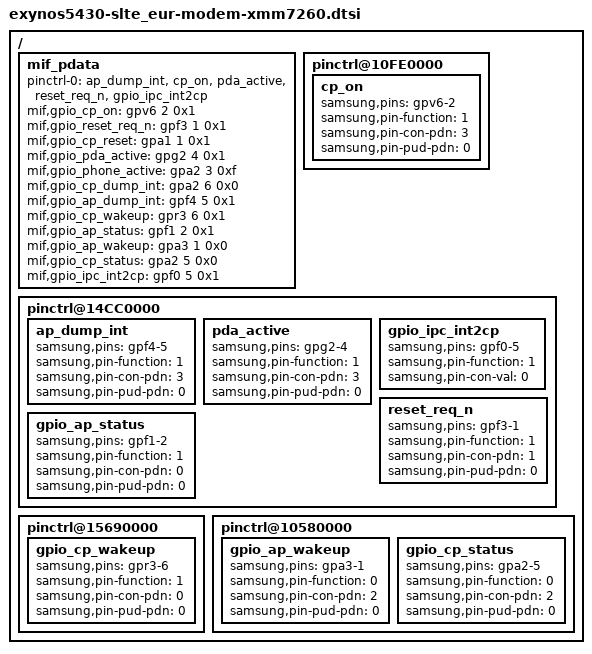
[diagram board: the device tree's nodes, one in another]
/*
 * SAMSUNG UNIVERSAL5430 board device tree source
 *
 * Copyright (c) 2013 Samsung Electronics Co., Ltd.
 *		http://www.samsung.com
 *
 * This program is free software; you can redistribute it and/or modify
 * it under the terms of the GNU General Public License version 2 as
 * published by the Free Software Foundation.
*/

#include "modem-xmm7260-pdata.dtsi"

/ {
	/* modem_interface_driver: Intel XMM7260 LTE Modem */
	mif_pdata {
		status = "okay";
		pinctrl-names = "default";
		pinctrl-0 = <&ap_dump_int &cp_on &pda_active &reset_req_n &gpio_ipc_int2cp>;

		mif,gpio_cp_on = <&gpv6 2 0x1>;
		mif,gpio_reset_req_n = <&gpf3 1 0x1>;
		mif,gpio_cp_reset = <&gpa1 1 0x1>;
		mif,gpio_pda_active = <&gpg2 4 0x1>;
		mif,gpio_phone_active = <&gpa2 3 0xf>;
		mif,gpio_cp_dump_int = <&gpa2 6 0x0>;
		mif,gpio_ap_dump_int = <&gpf4 5 0x1>;

		mif,gpio_cp_wakeup = <&gpr3 6 0x1>;
		mif,gpio_ap_status = <&gpf1 2 0x1>;
		mif,gpio_ap_wakeup = <&gpa3 1 0x0>;
		mif,gpio_cp_status = <&gpa2 5 0x0>;

		mif,gpio_ipc_int2cp = <&gpf0 5 0x1>;
	};

	pinctrl@10FE0000 {
		cp_on: cp_on {
			samsung,pins = "gpv6-2";
			samsung,pin-function = <1>;
			samsung,pin-con-pdn = <3>;
			samsung,pin-pud-pdn = <0>;
		};
	};

	pinctrl@14CC0000 {
		ap_dump_int: ap_dump_int {
			samsung,pins = "gpf4-5";
			samsung,pin-function = <1>;
			samsung,pin-con-pdn = <3>;
			samsung,pin-pud-pdn = <0>;
		};
		pda_active: pda_active {
			samsung,pins = "gpg2-4";
			samsung,pin-function = <1>;
			samsung,pin-con-pdn = <3>;
			samsung,pin-pud-pdn = <0>;
		};
		gpio_ipc_int2cp: gpio_ipc_int2cp {
			samsung,pins = "gpf0-5";
			samsung,pin-function = <1>;
			samsung,pin-con-val = <0>;
		};
		reset_req_n: reset_req_n {
			samsung,pins = "gpf3-1";
			samsung,pin-function = <1>;
			samsung,pin-con-pdn = <1>;
			samsung,pin-pud-pdn = <0>;
		};
		gpio_ap_status: gpio_ap_status {
			samsung,pins = "gpf1-2";
			samsung,pin-function = <1>;
			samsung,pin-con-pdn = <0>;
			samsung,pin-pud-pdn = <0>;
		};
	};

	pinctrl@15690000 {
		gpio_cp_wakeup: gpio_cp_wakeup {
			samsung,pins = "gpr3-6";
			samsung,pin-function = <1>;
			samsung,pin-con-pdn = <0>;
			samsung,pin-pud-pdn = <0>;
		};
	};

	pinctrl@10580000 {
		gpio_ap_wakeup: gpio_ap_wakeup {
			samsung,pins = "gpa3-1";
			samsung,pin-function = <0>;
			samsung,pin-con-pdn = <2>;
			samsung,pin-pud-pdn = <0>;
		};
		gpio_cp_status: gpio_cp_status {
			samsung,pins = "gpa2-5";
			samsung,pin-function = <0>;
			samsung,pin-con-pdn = <2>;
			samsung,pin-pud-pdn = <0>;
		};
	};

};

